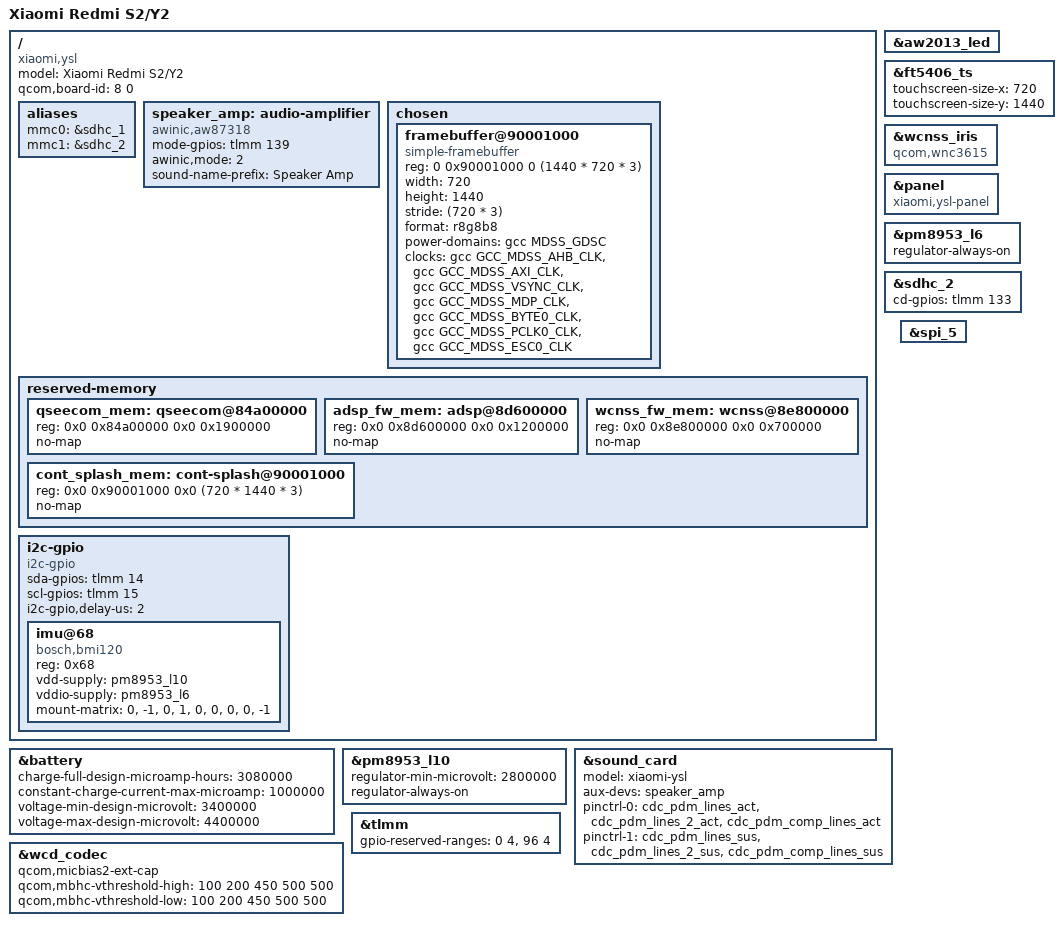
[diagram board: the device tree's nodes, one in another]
// SPDX-License-Identifier: BSD-3-Clause
/*
 * Copyright (c) 2023, Barnabas Czeman
 */
/dts-v1/;

#include "msm8953-xiaomi-common.dtsi"

/delete-node/ &adsp_fw_mem;
/delete-node/ &cont_splash_mem;
/delete-node/ &qseecom_mem;
/delete-node/ &wcnss_fw_mem;

/ {
	model = "Xiaomi Redmi S2/Y2";
	compatible = "xiaomi,ysl", "qcom,msm8953";
	qcom,board-id = <8 0>;

	aliases {
		mmc0 = &sdhc_1;
		mmc1 = &sdhc_2;
	};

	speaker_amp: audio-amplifier {
		compatible = "awinic,aw87318", "awinic,aw8738";
		mode-gpios = <&tlmm 139 GPIO_ACTIVE_HIGH>;
		awinic,mode = <2>;
		sound-name-prefix = "Speaker Amp";
	};

	chosen {
		#address-cells = <2>;
		#size-cells = <2>;
		ranges;

		framebuffer@90001000 {
			compatible = "simple-framebuffer";
			reg = <0 0x90001000 0 (1440 * 720 * 3)>;

			width = <720>;
			height = <1440>;
			stride = <(720 * 3)>;
			format = "r8g8b8";

			power-domains = <&gcc MDSS_GDSC>;

			clocks = <&gcc GCC_MDSS_AHB_CLK>,
				 <&gcc GCC_MDSS_AXI_CLK>,
				 <&gcc GCC_MDSS_VSYNC_CLK>,
				 <&gcc GCC_MDSS_MDP_CLK>,
				 <&gcc GCC_MDSS_BYTE0_CLK>,
				 <&gcc GCC_MDSS_PCLK0_CLK>,
				 <&gcc GCC_MDSS_ESC0_CLK>;
		};
	};

	reserved-memory {
		qseecom_mem: qseecom@84a00000 {
			reg = <0x0 0x84a00000 0x0 0x1900000>;
			no-map;
		};

		adsp_fw_mem: adsp@8d600000 {
			reg = <0x0 0x8d600000 0x0 0x1200000>;
			no-map;
		};

		wcnss_fw_mem: wcnss@8e800000 {
			reg = <0x0 0x8e800000 0x0 0x700000>;
			no-map;
		};

		cont_splash_mem: cont-splash@90001000 {
			reg = <0x0 0x90001000 0x0 (720 * 1440 * 3)>;
			no-map;
		};
	};

	i2c-gpio {
		compatible = "i2c-gpio";
		sda-gpios = <&tlmm 14 (GPIO_ACTIVE_HIGH|GPIO_OPEN_DRAIN)>;
		scl-gpios = <&tlmm 15 (GPIO_ACTIVE_HIGH|GPIO_OPEN_DRAIN)>;
		i2c-gpio,delay-us = <2>; /* ~100 kHz */
		#address-cells = <1>;
		#size-cells = <0>;

		imu@68 {
			compatible = "bosch,bmi120";
			reg = <0x68>;

			vdd-supply = <&pm8953_l10>;
			vddio-supply = <&pm8953_l6>;

			mount-matrix = "0", "-1", "0",
					"1", "0", "0",
					"0", "0", "-1";
		};
	};
};

&aw2013_led {
	status = "okay";
};

&battery {
	charge-full-design-microamp-hours = <3080000>;
	constant-charge-current-max-microamp = <1000000>;
	voltage-min-design-microvolt = <3400000>;
	voltage-max-design-microvolt = <4400000>;
};

&ft5406_ts {
	touchscreen-size-x = <720>;
	touchscreen-size-y = <1440>;

	status = "okay";
};

&wcnss_iris {
	compatible = "qcom,wnc3615", "qcom,wcn3620";
};

&panel {
	compatible = "xiaomi,ysl-panel";
};

&pm8953_l6 {
	regulator-always-on;
};

&pm8953_l10 {
	regulator-min-microvolt = <2800000>;
	regulator-always-on;
};

&sdhc_2 {
	cd-gpios = <&tlmm 133 GPIO_ACTIVE_HIGH>;
};

&sound_card {
	model = "xiaomi-ysl";

	aux-devs = <&speaker_amp>;

	pinctrl-names = "default", "sleep";
	pinctrl-0 = <&cdc_pdm_lines_act &cdc_pdm_lines_2_act &cdc_pdm_comp_lines_act>;
	pinctrl-1 = <&cdc_pdm_lines_sus &cdc_pdm_lines_2_sus &cdc_pdm_comp_lines_sus>;

	status = "okay";
};

&spi_5 {
	status = "okay";
};

&wcd_codec {
	qcom,micbias2-ext-cap;
	qcom,mbhc-vthreshold-high = <100 200 450 500 500>;
	qcom,mbhc-vthreshold-low = <100 200 450 500 500>;
};

&tlmm {
	gpio-reserved-ranges = <0 4>, <96 4>;
};
